VERSION ""

NS_ :

BS_:

BU_: RADAR

BO_ 512 RadarCfg: 8 XXX
 SG_ MaxDistanceValid : 0|1@0+ (1,0) [0|1] "" XXX
 SG_ SensorIDValid : 1|1@0+ (1,0) [0|1] "" XXX
 SG_ RadarPowerValid : 2|1@0+ (1,0) [0|1] "" XXX
 SG_ OutputTypeValid : 3|1@0+ (1,0) [0|1] "" XXX
 SG_ SendQualityValid : 4|1@0+ (1,0) [0|1] "" XXX
 SG_ SendExtInfoValid : 5|1@0+ (1,0) [0|1] "" XXX
 SG_ SortIndexValid : 6|1@0+ (1,0) [0|1] "" XXX
 SG_ StoreInNvmValid : 7|1@0+ (1,0) [0|1] "" XXX
 SG_ MaxDistance : 15|10@0+ (2,0) [0|2046] "m" XXX
 SG_ SensorID : 34|3@0+ (1,0) [0|7] "" XXX
 SG_ OutputType : 36|3@0+ (1,0) [0|7] "" XXX
 SG_ RadarPower : 39|3@0+ (1,0) [0|7] "" XXX
 SG_ SendQuality : 42|1@0+ (1,0) [0|1] "" XXX
 SG_ SendExtInfo : 43|1@0+ (1,0) [0|1] "" XXX
 SG_ SortIndex : 46|3@0+ (1,0) [0|7] "" XXX
 SG_ StoreNvm : 47|1@0+ (1,0) [0|1] "" XXX
 SG_ RCSThresholdValid : 48|1@0+ (1,0) [0|1] "" XXX
 SG_ RCSThreshold : 51|3@1+ (1,0) [0|7] "" XXX
 SG_ InterfaceType : 53|2@0+ (1,0) [0|3] "" XXX
 SG_ InterfaceSelectValid : 55|1@0+ (1,0) [0|1] "" XXX
 SG_ LVDSSelect : 56|1@0+ (1,0) [0|1] "" XXX
 SG_ CalibrationEnabled : 58|2@0+ (1,0) [0|3] "" XXX
 SG_ CalibrationValid : 59|1@0+ (1,0) [0|1] "" XXX
 SG_ BaudRateValid : 60|1@0+ (1,0) [0|1] "" XXX
 SG_ BaudRate : 63|3@0+ (1,0) [0|7] "" XXX

VAL_ 512 MaxDistanceValid 0 "Invalid" 1 "Valid";
VAL_ 512 SensorIDValid 0 "Invalid" 1 "Valid";
VAL_ 512 RadarPowerValid 0 "Invalid" 1 "Valid";
VAL_ 512 OutputTypeValid 0 "Invalid" 1 "Valid";
VAL_ 512 SendQualityValid 0 "Invalid" 1 "Valid";
VAL_ 512 SendExtInfoValid 0 "Invalid" 1 "Valid";
VAL_ 512 SortIndexValid 0 "Invalid" 1 "Valid";
VAL_ 512 StoreInNvmValid 0 "Invalid" 1 "Valid";
VAL_ 512 OutputType 0 "None" 1 "Objects" 2 "Clusters";
VAL_ 512 RadarPower 0 "Standard" 1 "-3dB Gain" 2 "-6dB Gain" 3 "-9dB Gain";
VAL_ 512 SendQuality 0 "Off" 1 "On";
VAL_ 512 SendExtInfo 0 "Off" 1 "On";
VAL_ 512 SortIndex 0 "No Sorting" 1 "Sort By Range" 2 "Sort By RCS";
VAL_ 512 StoreNvm 0 "Inactive" 1 "Active";
VAL_ 512 RCSThresholdValid 0 "Invalid" 1 "Valid";
VAL_ 512 RCSThreshold 0 "Standard" 1 "High Sensitivity";
VAL_ 512 CalibrationValid 0 "Invalid" 1 "Valid";
VAL_ 512 CalibrationEnabled 0 "Disabled" 1 "Enabled" 2 "Restore to default values";
VAL_ 512 InterfaceSelectValid 0 "Invalid" 1 "Valid";
VAL_ 512 BaudRateValid 0 "Invalid" 1 "Valid";
VAL_ 512 BaudRate 0 "500K (Default)" 1 "250K" 2 "1M";

BO_ 513 RadarState: 8 XXX
 SG_ NVMReadStatus : 6|1@0+ (1,0) [0|1] "" XXX
 SG_ NVMWriteStatus : 7|1@0+ (1,0) [0|1] "" XXX
 SG_ MaxDistanceCfg : 15|10@0+ (2,0) [0|2046] "m" XXX
 SG_ RadarPowerCfg : 25|3@0+ (1,0) [0|7] "" XXX
 SG_ SensorID : 34|3@0+ (1,0) [0|7] "" XXX
 SG_ SortIndex : 38|3@0+ (1,0) [0|7] "" XXX
 SG_ CtrlRelayCfg : 41|1@0+ (1,0) [0|1] "" XXX
 SG_ OutputTypeCfg : 43|2@0+ (1,0) [0|3] "" XXX
 SG_ SendQualityCfg : 44|1@0+ (1,0) [0|1] "" XXX
 SG_ SendExtInfoCfg : 45|1@0+ (1,0) [0|1] "" XXX
 SG_ MotionRxState : 47|2@0+ (1,0) [0|3] "" XXX
 SG_ CanBaudRate : 55|3@0+ (1,0) [0|7] "" XXX
 SG_ InterfaceType : 57|2@0+ (1,0) [0|3] "" XXX
 SG_ RCSThreshold : 60|3@1+ (1,0) [0|7] "" XXX
 SG_ LVDSSelect : 61|1@0+ (1,0) [0|1] "" XXX
 SG_ CalibrationEnabled : 63|2@1+ (1,0) [0|3] "" XXX

VAL_ 513 NVMReadStatus 0 "Failed" 1 "Successful";
VAL_ 513 NVMWriteStatus 0 "Failed" 1 "Successful";
VAL_ 513 SortIndex 0 "No Sorting" 1 "Sort By Range" 2 "Sort By RCS";
VAL_ 513 RadarPowerCfg 0 "Standard" 1 "-3dB Gain" 2 "-6dB Gain" 3 "-9dB Gain";
VAL_ 513 OutputTypeCfg 0 "None" 1 "Objects" 2 "Clusters";
VAL_ 513 CANBaudRate 0 "500K (Default)" 1 "250K" 2 "1M";
VAL_ 513 RCSThreshold 0 "Standard" 1 "High Sensitivity";
VAL_ 512 CalibrationEnabled 0 "Disabled" 1 "Enabled" 2 "Restore to default values";

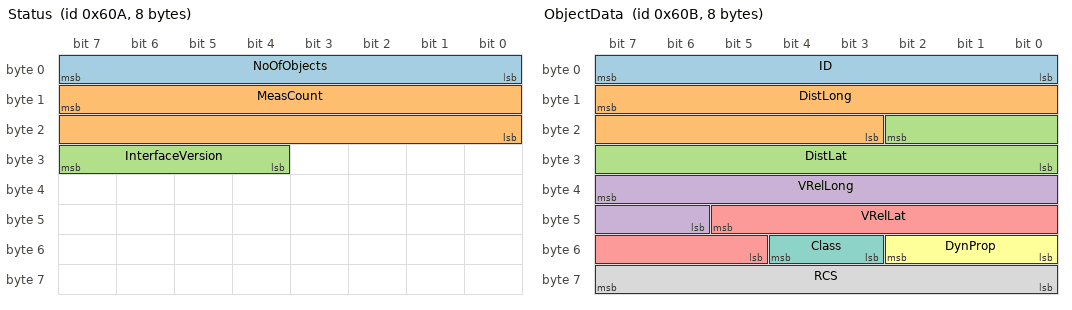
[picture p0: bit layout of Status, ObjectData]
BO_ 1546 Status: 8 RADAR
 SG_ NoOfObjects : 7|8@0+ (1,0) [0|255] "" XXX
 SG_ MeasCount : 15|16@0+ (1,0) [0|65535] "" XXX
 SG_ InterfaceVersion : 31|4@0+ (1,0) [0|15] "" XXX

BO_ 1547 ObjectData: 8 RADAR
 SG_ ID : 7|8@0+ (1,0) [0|255] "" XXX
 SG_ DistLong : 15|13@0+ (0.2,-500) [-500|1138.2] "m" XXX
 SG_ DistLat : 18|11@0+ (0.2,-204.6) [-204.6|204.8] "m" XXX
 SG_ VRelLong : 39|10@0+ (0.25,-128) [-128|127.75] "m/s" XXX
 SG_ VRelLat : 45|9@0+ (0.25,-64) [-64|63.75] "m/s" XXX
 SG_ DynProp : 50|3@0+ (1,0) [0|7] "" XXX
 SG_ Class : 52|2@0+ (1,0) [0|3] "" XXX
 SG_ RCS : 63|8@0+ (0.5,-64) [-64|63.75] "dBm2" XXX

CM_ BO_ 1547 "Object detection and tracking information";
VAL_ 1547 DynProp 0 "moving" 1 "stationary" 2 "oncoming" 3 "crossing_left" 4 "crossing_right" 5 "unknown" 6 "stopped";
VAL_ 1547 Class 0 "point" 1 "vehicle" 2 "reserved" 3 "reserved";
